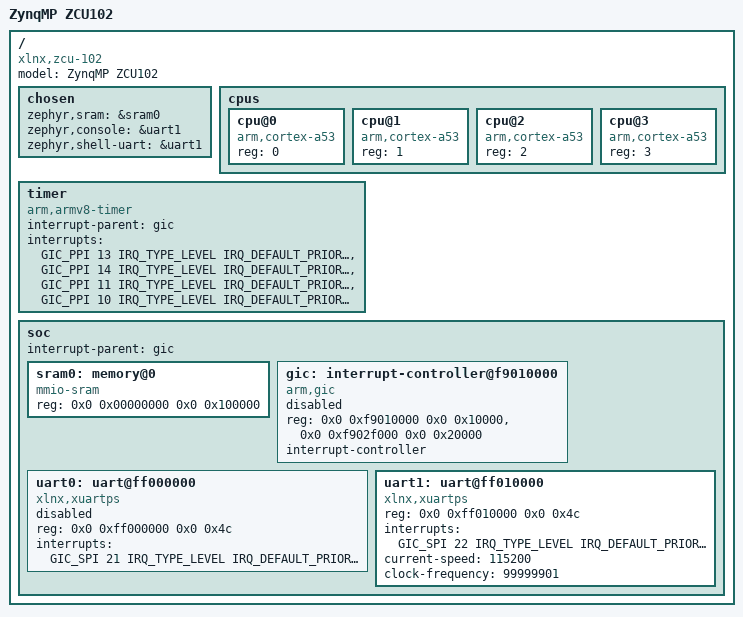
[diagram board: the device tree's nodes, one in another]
/*
 * Copyright (c) 2023 Linaro
 *
 * SPDX-License-Identifier: Apache-2.0
 *
 */

 /dts-v1/;
 #include <mem.h>
 #include <arm64/armv8-a.dtsi>
 #include <zephyr/dt-bindings/interrupt-controller/arm-gic.h>

 / {

	model = "ZynqMP ZCU102";
	compatible = "xlnx,zcu-102";

	chosen {
		zephyr,sram = &sram0;
		zephyr,console = &uart1;
		zephyr,shell-uart = &uart1;
	};

	cpus {
		#address-cells = <1>;
		#size-cells = <0>;

		cpu@0 {
			device_type = "cpu";
			compatible = "arm,cortex-a53";
			reg = <0>;
		};

		cpu@1 {
			device_type = "cpu";
			compatible = "arm,cortex-a53";
			reg = <1>;
		};

		cpu@2 {
			device_type = "cpu";
			compatible = "arm,cortex-a53";
			reg = <2>;
		};

		cpu@3 {
			device_type = "cpu";
			compatible = "arm,cortex-a53";
			reg = <3>;
		};
	};

	timer {
		compatible = "arm,armv8-timer";
		interrupt-parent = <&gic>;
		interrupts = <GIC_PPI 13 IRQ_TYPE_LEVEL
				IRQ_DEFAULT_PRIORITY>,
				<GIC_PPI 14 IRQ_TYPE_LEVEL
				IRQ_DEFAULT_PRIORITY>,
				<GIC_PPI 11 IRQ_TYPE_LEVEL
				IRQ_DEFAULT_PRIORITY>,
				<GIC_PPI 10 IRQ_TYPE_LEVEL
				IRQ_DEFAULT_PRIORITY>;
	};

	soc {
		#address-cells = <2>;
		#size-cells = <2>;

		sram0: memory@0 {
			compatible = "mmio-sram";
			reg = <0x0 0x00000000 0x0 0x100000>;
		};

		interrupt-parent = <&gic>;

		gic: interrupt-controller@f9010000 {
			compatible = "arm,gic";
			reg = <0x0 0xf9010000 0x0 0x10000>,
				<0x0 0xf902f000 0x0 0x20000>;
			interrupt-controller;
			#interrupt-cells = <4>;
			status = "disabled";
		};


		uart0: uart@ff000000 {
			compatible = "xlnx,xuartps";
			reg = <0x0 0xff000000 0x0 0x4c>;
			status = "disabled";
			interrupts = <GIC_SPI 21 IRQ_TYPE_LEVEL
					IRQ_DEFAULT_PRIORITY>;
			interrupt-names = "irq_0";
		};

		uart1: uart@ff010000 {
			compatible = "xlnx,xuartps";
			reg = <0x0 0xff010000 0x0 0x4c>;
			status = "disabled";
			interrupts = <GIC_SPI 22 IRQ_TYPE_LEVEL
					IRQ_DEFAULT_PRIORITY>;
			interrupt-names = "irq_0";
		};

	 };
 };

 &uart1 {
	current-speed = < 115200 >;
	status = "okay";
	clock-frequency = <99999901>;
 };
